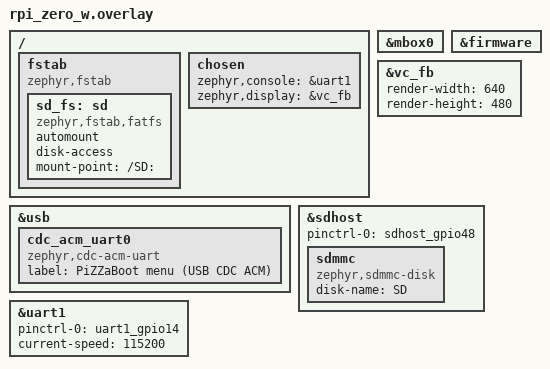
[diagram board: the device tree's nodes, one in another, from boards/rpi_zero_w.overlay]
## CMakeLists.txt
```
# SPDX-License-Identifier: Apache-2.0

cmake_minimum_required(VERSION 3.20.0)

find_package(Zephyr REQUIRED HINTS $ENV{ZEPHYR_BASE})
project(pizzaboot)

# USB CDC ACM menu mirror needs the usbd_context init helper from the
# Zephyr USB samples (same pattern as PizzaShell).
if(CONFIG_USB_DEVICE_STACK_NEXT)
  include(${ZEPHYR_BASE}/samples/subsys/usb/common/common.cmake)
endif()

target_sources(app PRIVATE
  src/main.c
  src/hdmi.c
  ../lib/bootsel/bootsel.c
)
target_include_directories(app PRIVATE ../lib ../lib/bootsel)
```

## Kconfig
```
# SPDX-License-Identifier: Apache-2.0

# Pull in the SAMPLE_USBD_* options used by sample_usbd_init.c (VID, PID,
# manufacturer/product strings) for the CDC menu mirror.
source "samples/subsys/usb/common/Kconfig.sample_usbd"

source "Kconfig.zephyr"
```

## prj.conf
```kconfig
# SPDX-License-Identifier: Apache-2.0
#
# PiZZaBoot -- Tier-1 boot menu. Deliberately dumb: no shell, no
# networking, no BT. Menu on mini-UART + USB CDC + HDMI; boots fast.

CONFIG_PRINTK=y
CONFIG_MAIN_STACK_SIZE=8192

CONFIG_SERIAL=y
CONFIG_UART_CONSOLE=y
CONFIG_UART_LINE_CTRL=y

CONFIG_GPIO=y

CONFIG_FILE_SYSTEM=y
CONFIG_FAT_FILESYSTEM_ELM=y
CONFIG_FS_FATFS_LFN=y
CONFIG_FS_FATFS_LFN_MODE_STACK=y

CONFIG_LOG=y
CONFIG_LOG_MODE_DEFERRED=y
CONFIG_LOG_BACKEND_UART=y
```

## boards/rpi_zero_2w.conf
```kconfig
# SPDX-License-Identifier: Apache-2.0
#
# PiZZaBoot on the Pi Zero 2 W: VC firmware mailbox (USB PHY power +
# HDMI fb), SDHost storage for the boot FAT, USB CDC menu mirror.

CONFIG_RASPBERRYPI_FIRMWARE=y

# HDMI menu via the VideoCore framebuffer
CONFIG_DISPLAY=y
CONFIG_BCM2835_FB=y

# Boot FAT on the microSD (SDHost); fstab automount in the overlay.
CONFIG_DISK_ACCESS=y
CONFIG_DISK_DRIVERS=y
CONFIG_SDMMC_SUBSYS=y
CONFIG_FS_FATFS_FSTAB_AUTOMOUNT=y
# Never reformat the boot card on a mount failure.
CONFIG_FILE_SYSTEM_MKFS=n
CONFIG_FS_FATFS_MOUNT_MKFS=n

# USB device stack -- CDC ACM menu mirror
CONFIG_USB_DEVICE_STACK_NEXT=y
CONFIG_UDC_DWC2=y
CONFIG_UDC_DWC2_DMA=n
CONFIG_USBD_CDC_ACM_CLASS=y
CONFIG_CDC_ACM_SERIAL_INITIALIZE_AT_BOOT=n
CONFIG_SAMPLE_USBD_PRODUCT="PiZZaBoot menu"
CONFIG_SAMPLE_USBD_MANUFACTURER="jetpax/PiZZa"
CONFIG_SAMPLE_USBD_PID=0xCAFE
# AArch64 USBD/UDC stacks: upstream defaults overflow.
CONFIG_USBD_THREAD_STACK_SIZE=4096
CONFIG_UDC_DWC2_STACK_SIZE=4096
CONFIG_UDC_DRIVER_LOG_LEVEL_WRN=y
CONFIG_USBD_CDC_ACM_LOG_LEVEL_WRN=y
CONFIG_USBD_LOG_LEVEL_WRN=y

# Bring-up nets; strip once M1 signs off.
CONFIG_STACK_SENTINEL=y
CONFIG_ASSERT=y
```

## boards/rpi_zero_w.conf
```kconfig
# SPDX-License-Identifier: Apache-2.0
#
# PiZZaBoot on the original Pi Zero W: VC firmware mailbox (USB PHY
# power + HDMI fb), SDHost storage for the boot FAT, USB CDC menu
# mirror. Mirrors the Zero 2 W config; the differences are noted.

CONFIG_RASPBERRYPI_FIRMWARE=y

# HDMI menu via the VideoCore framebuffer. The overlay pins a 640x480
# render size, so the buffer is 1.2 MB and fits the default 8 MiB
# KERNEL_VM_SIZE. Dropping render-width/height to take the monitor's
# native mode would need that raised -- a 1080p buffer is 8355840 bytes
# on its own and device_map() panics without the headroom.
CONFIG_DISPLAY=y
CONFIG_BCM2835_FB=y

# Boot FAT on the microSD (SDHost); fstab automount in the overlay.
CONFIG_DISK_ACCESS=y
CONFIG_DISK_DRIVERS=y
CONFIG_SDMMC_SUBSYS=y
CONFIG_FS_FATFS_FSTAB_AUTOMOUNT=y
# Never reformat the boot card on a mount failure.
CONFIG_FILE_SYSTEM_MKFS=n
CONFIG_FS_FATFS_MOUNT_MKFS=n

# USB device stack -- CDC ACM menu mirror
CONFIG_USB_DEVICE_STACK_NEXT=y
CONFIG_UDC_DWC2=y
CONFIG_UDC_DWC2_DMA=n
CONFIG_USBD_CDC_ACM_CLASS=y
CONFIG_CDC_ACM_SERIAL_INITIALIZE_AT_BOOT=n
CONFIG_SAMPLE_USBD_PRODUCT="PiZZaBoot menu"
CONFIG_SAMPLE_USBD_MANUFACTURER="jetpax/PiZZa"
CONFIG_SAMPLE_USBD_PID=0xCAFE
CONFIG_USBD_THREAD_STACK_SIZE=4096
CONFIG_UDC_DWC2_STACK_SIZE=4096
CONFIG_UDC_DRIVER_LOG_LEVEL_WRN=y
CONFIG_USBD_CDC_ACM_LOG_LEVEL_WRN=y
CONFIG_USBD_LOG_LEVEL_WRN=y

# Bring-up nets; strip once the Zero W menu signs off on hardware.
CONFIG_STACK_SENTINEL=y
CONFIG_ASSERT=y
```

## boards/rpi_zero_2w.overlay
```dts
/*
 * PiZZaBoot -- rpi_zero_2w overlay.
 *
 * Menu console on the mini-UART (GPIO14/15 @ 115200, per the canonical
 * config.txt enable_uart=1), mirrored on USB CDC ACM. HDMI list drawn
 * into a 640x480 virtual framebuffer that the VideoCore HVS upscales
 * to the monitor's native mode (render-width/render-height).
 */

&mbox0 {
	status = "okay";
};

&firmware {
	status = "okay";
};

&vc_fb {
	render-width = <640>;
	render-height = <480>;
	status = "okay";
};

&usb {
	status = "okay";

	cdc_acm_uart0: cdc_acm_uart0 {
		compatible = "zephyr,cdc-acm-uart";
		label = "PiZZaBoot menu (USB CDC ACM)";
	};
};

/ {
	fstab {
		compatible = "zephyr,fstab";

		sd_fs: sd {
			compatible = "zephyr,fstab,fatfs";
			automount;
			disk-access;
			mount-point = "/SD:";
		};
	};

	chosen {
		zephyr,console = &uart1;
		zephyr,display = &vc_fb;
	};
};

&uart1 {
	pinctrl-names = "default";
	pinctrl-0 = <&uart1_gpio14>;
	status = "okay";
	current-speed = <115200>;
};
```

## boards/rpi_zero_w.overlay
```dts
/*
 * PiZZaBoot -- rpi_zero_w overlay.
 *
 * Menu console on the mini-UART (GPIO14/15 @ 115200, per the canonical
 * config.txt enable_uart=1), mirrored on USB CDC ACM. HDMI list drawn
 * into a 640x480 virtual framebuffer that the VideoCore HVS upscales
 * to the monitor's native mode (render-width/render-height) -- the
 * same arrangement as the Zero 2 W, and it keeps the framebuffer at
 * 1.2 MB so the default 8 MiB kernel VM window is ample.
 *
 * Unlike the Zero 2 W, &sdhost is disabled in the SoC DTS and needs
 * its ALT0 mux (GPIO 48..53) named here.
 */

&mbox0 {
	status = "okay";
};

&firmware {
	status = "okay";
};

&vc_fb {
	render-width = <640>;
	render-height = <480>;
	status = "okay";
};

&usb {
	status = "okay";

	cdc_acm_uart0: cdc_acm_uart0 {
		compatible = "zephyr,cdc-acm-uart";
		label = "PiZZaBoot menu (USB CDC ACM)";
	};
};

/* Legacy SDHost controller -> external microSD slot, which carries the
 * boot FAT this menu reads menu.txt and chosen.txt from.
 */
&sdhost {
	pinctrl-names = "default";
	pinctrl-0 = <&sdhost_gpio48>;
	status = "okay";

	sdmmc {
		compatible = "zephyr,sdmmc-disk";
		disk-name = "SD";
	};
};

/ {
	fstab {
		compatible = "zephyr,fstab";

		sd_fs: sd {
			compatible = "zephyr,fstab,fatfs";
			automount;
			disk-access;
			mount-point = "/SD:";
		};
	};

	chosen {
		zephyr,console = &uart1;
		zephyr,display = &vc_fb;
	};
};

&uart1 {
	pinctrl-names = "default";
	pinctrl-0 = <&uart1_gpio14>;
	status = "okay";
	current-speed = <115200>;
};
```

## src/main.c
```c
/*
 * Copyright (c) 2026 jetpax <jetpax@users.noreply.github.com>
 * SPDX-License-Identifier: Apache-2.0
 *
 * PiZZaBoot -- the Tier-1 GRUB-style boot menu (WO-T1 M1).
 *
 * The GPU firmware is the actual boot selector: config.txt defaults to
 * this menu, `include chosen.txt` overrides it with the persisted
 * choice, and holding the GPIO17 button at power-on forces the menu
 * back. This app only has to render a list, take a pick, write
 * chosen.txt (atomically -- bootsel_set_kernel), and reset.
 *
 * UI surfaces, all driven from one poll loop:
 *   - mini-UART (115200 on GPIO14/15) -- ANSI menu, always on
 *   - USB CDC ACM -- same menu, mirrored while DTR is up
 *   - HDMI -- 8x8-font list (hdmi.c), optional
 *   - GPIO17 button -- short press = next entry, long press = boot
 *
 * Entries come from menu.txt on the boot FAT ("Name = file.bin" lines,
 * plus "timeout =" / "default ="); fallback is a *.bin scan. A countdown
 * to the default entry runs only when no valid chosen.txt exists (fresh
 * card); when the menu was summoned over a valid choice (the button
 * path), it waits for the user.
 */

#include <zephyr/kernel.h>
#include <zephyr/device.h>
#include <zephyr/devicetree.h>
#include <zephyr/drivers/uart.h>
#include <zephyr/drivers/gpio.h>
#include <zephyr/fs/fs.h>
#include <zephyr/sys/printk.h>
#include <stdarg.h>
#include <stdio.h>
#include <stdlib.h>
#include <string.h>

#include "bootsel.h"
#include "pizzaboot.h"

#if IS_ENABLED(CONFIG_USB_DEVICE_STACK_NEXT)
#include <zephyr/usb/usbd.h>
#include <sample_usbd.h>
#endif

#define MOUNT      "/SD:"
#define MENU_TXT   MOUNT "/menu.txt"
#define CHOSEN_TXT MOUNT "/chosen.txt"

#define DEFAULT_TIMEOUT_S 5
#define LONG_PRESS_MS     700
#define ESC_TIMEOUT_MS    60

/* --- boot entries ----------------------------------------------------------- */

static struct pb_entry entries[PB_MAX_ENTRIES];
static int entry_count;
static int menu_timeout_s = DEFAULT_TIMEOUT_S;
static char default_name[PB_NAME_LEN];

/* --- console mux ------------------------------------------------------------ */

enum key {
	K_NONE = 0,
	K_UP,
	K_DOWN,
	K_ENTER,
	K_OTHER,		/* any other key: cancels the countdown */
	K_DIGIT_BASE = 100,	/* K_DIGIT_BASE + i = entry i */
};

struct con {
	const struct device *dev;
	bool cdc;
	bool active;
	int esc;		/* 0 idle, 1 got ESC, 2 got ESC[ */
	int64_t esc_t;
};

static struct con cons[2];
static int con_count;

static void con_putc(char c)
{
	for (int i = 0; i < con_count; i++) {
		if (!cons[i].active) {
			continue;
		}
		if (c == '\n') {
			uart_poll_out(cons[i].dev, '\r');
		}
		uart_poll_out(cons[i].dev, c);
	}
}

static void con_puts(const char *s)
{
	for (; *s != '\0'; s++) {
		con_putc(*s);
	}
}

static void __printf_like(1, 2) con_printf(const char *fmt, ...)
{
	char buf[192];
	va_list ap;

	va_start(ap, fmt);
	vsnprintf(buf, sizeof(buf), fmt, ap);
	va_end(ap);
	con_puts(buf);
}

/* Throw away anything sitting in the RX FIFOs -- power-on line noise
 * lands there before the loop starts and must not cancel the countdown.
 */
static void con_drain(void)
{
	unsigned char junk;

	for (int i = 0; i < con_count; i++) {
		while (uart_poll_in(cons[i].dev, &junk) == 0) {
		}
	}
}

static enum key con_poll_key(struct con *c)
{
	unsigned char ch;

	while (uart_poll_in(c->dev, &ch) == 0) {
		if (c->esc == 1) {
			if (ch == '[') {
				c->esc = 2;
				continue;
			}
			c->esc = (ch == 0x1b) ? 1 : 0;
			continue;
		}
		if (c->esc == 2) {
			c->esc = 0;
			if (ch == 'A') {
				return K_UP;
			}
			if (ch == 'B') {
				return K_DOWN;
			}
			continue;
		}
		if (ch == 0x1b) {
			c->esc = 1;
			c->esc_t = k_uptime_get();
			continue;
		}
		if (ch == '\r' || ch == '\n') {
			return K_ENTER;
		}
		if (ch >= '1' && ch <= '9') {
			return (enum key)(K_DIGIT_BASE + (ch - '1'));
		}
		/* 0x00/0xFF are power-on line glitches, not keys. */
		if (ch == 0x00 || ch == 0xFF) {
			continue;
		}
		return K_OTHER;
	}

	/* Bare ESC (no sequence followed): treat as "a key". */
	if (c->esc == 1 && (k_uptime_get() - c->esc_t) > ESC_TIMEOUT_MS) {
		c->esc = 0;
		return K_OTHER;
	}
	return K_NONE;
}

/* --- USB CDC ---------------------------------------------------------------- */

#if IS_ENABLED(CONFIG_USB_DEVICE_STACK_NEXT)
static void usbd_cb(struct usbd_context *const ctx,
		    const struct usbd_msg *const msg)
{
	ARG_UNUSED(ctx);
	ARG_UNUSED(msg);
	/* DTR is polled from the main loop; nothing to do here. */
}

static void usb_start(void)
{
	struct usbd_context *usbd = sample_usbd_init_device(usbd_cb);

	if (usbd == NULL) {
		printk("[pizzaboot] usbd init failed\n");
		return;
	}
	if (!usbd_can_detect_vbus(usbd)) {
		int err = usbd_enable(usbd);

		if (err != 0) {
			printk("[pizzaboot] usbd_enable: %d\n", err);
		}
	}
}

static bool cdc_dtr(const struct device *dev)
{
	uint32_t dtr = 0U;

	(void)uart_line_ctrl_get(dev, UART_LINE_CTRL_DTR, &dtr);
	return dtr != 0U;
}
#else
static void usb_start(void)
{
}
#endif

/* --- GPIO17 button ----------------------------------------------------------- */

static const struct device *gpio0_dev;
static bool btn_ok;
static bool btn_down;
static bool btn_swallow;
static int64_t btn_t0;

static void button_init(void)
{
	gpio0_dev = DEVICE_DT_GET(DT_NODELABEL(gpio0));
	if (!device_is_ready(gpio0_dev)) {
		printk("[pizzaboot] gpio0 not ready, button off\n");
		return;
	}
	if (gpio_pin_configure(gpio0_dev, 17, GPIO_INPUT) == 0) {
		btn_ok = true;
		/* If the button is still down from summoning the menu
		 * (the firmware [gpio17=0] path), that press belongs to
		 * the firmware, not to us: swallow it until released.
		 */
		btn_swallow = gpio_pin_get_raw(gpio0_dev, 17) == 0;
	}
}

/* Short press = K_DOWN (cycle), long press = K_ENTER (boot). The pin
 * idles high (firmware gpio=17=ip,pu; button to GND), so pressed == 0.
 */
static enum key button_poll(void)
{
	if (!btn_ok) {
		return K_NONE;
	}

	bool pressed = gpio_pin_get_raw(gpio0_dev, 17) == 0;
	int64_t now = k_uptime_get();

	if (btn_swallow) {
		if (!pressed) {
			btn_swallow = false;
		}
		return K_NONE;
	}

	if (pressed && !btn_down) {
		btn_down = true;
		btn_t0 = now;
	} else if (!pressed && btn_down) {
		btn_down = false;
		if (now - btn_t0 >= LONG_PRESS_MS) {
			return K_ENTER;
		}
		if (now - btn_t0 >= 30) {	/* debounce */
			return K_DOWN;
		}
	}
	return K_NONE;
}

/* --- menu.txt ---------------------------------------------------------------- */

static char *trim(char *s)
{
	while (*s == ' ' || *s == '\t') {
		s++;
	}
	char *e = s + strlen(s);

	while (e > s && (e[-1] == ' ' || e[-1] == '\t' ||
			 e[-1] == '\r' || e[-1] == '\n')) {
		*--e = '\0';
	}
	return s;
}

static bool str_ieq(const char *a, const char *b)
{
	for (; *a != '\0' && *b != '\0'; a++, b++) {
		if ((*a | 0x20) != (*b | 0x20)) {
			return false;
		}
	}
	return *a == *b;
}

static int load_menu_txt(void)
{
	static char buf[2048];
	struct fs_file_t f;
	ssize_t n;

	fs_file_t_init(&f);
	if (fs_open(&f, MENU_TXT, FS_O_READ) != 0) {
		return 0;
	}
	n = fs_read(&f, buf, sizeof(buf) - 1);
	(void)fs_close(&f);
	if (n <= 0) {
		return 0;
	}
	buf[n] = '\0';

	int count = 0;
	char *save = NULL;

	for (char *line = strtok_r(buf, "\n", &save); line != NULL;
	     line = strtok_r(NULL, "\n", &save)) {
		char *s = trim(line);

		if (s[0] == '\0' || s[0] == '#') {
			continue;
		}
		char *eq = strchr(s, '=');

		if (eq == NULL) {
			continue;
		}
		*eq = '\0';
		char *key = trim(s);
		char *val = trim(eq + 1);

		if (str_ieq(key, "timeout")) {
			menu_timeout_s = atoi(val);
			continue;
		}
		if (str_ieq(key, "default")) {
			strncpy(default_name, val, sizeof(default_name) - 1);
			continue;
		}
		if (count < PB_MAX_ENTRIES && key[0] != '\0' &&
		    val[0] != '\0') {
			strncpy(entries[count].name, key, PB_NAME_LEN - 1);
			strncpy(entries[count].file, val, PB_FILE_LEN - 1);
			count++;
		}
	}
	return count;
}

/* Fallback when menu.txt is absent: every *.bin at the FAT root except
 * the GPU blob. Display name = filename minus .bin.
 */
static int scan_bins(void)
{
	struct fs_dir_t d;
	struct fs_dirent ent;
	int count = 0;

	fs_dir_t_init(&d);
	if (fs_opendir(&d, MOUNT) != 0) {
		return 0;
	}
	while (count < PB_MAX_ENTRIES && fs_readdir(&d, &ent) == 0 &&
	       ent.name[0] != '\0') {
		if (ent.type != FS_DIR_ENTRY_FILE || ent.name[0] == '.') {
			continue;
		}
		size_t len = strlen(ent.name);

		if (len < 5 || len >= PB_FILE_LEN ||
		    !str_ieq(ent.name + len - 4, ".bin")) {
			continue;
		}
		if (str_ieq(ent.name, "bootcode.bin")) {
			continue;
		}
		strncpy(entries[count].file, ent.name, PB_FILE_LEN - 1);
		memcpy(entries[count].name, ent.name,
		       MIN(len - 4, PB_NAME_LEN - 1));
		count++;
	}
	fs_closedir(&d);
	return count;
}

static void validate_entries(void)
{
	char path[PB_FILE_LEN + 8];
	struct fs_dirent st;

	for (int i = 0; i < entry_count; i++) {
		snprintf(path, sizeof(path), MOUNT "/%s", entries[i].file);
		entries[i].present = (fs_stat(path, &st) == 0 &&
				      st.type == FS_DIR_ENTRY_FILE);
	}
}

/* A valid chosen.txt means the firmware would have booted it -- we are
 * here because the button forced the menu, so no auto-boot countdown.
 */
static bool chosen_is_valid(void)
{
	char buf[64];
	char path[PB_FILE_LEN + 8];
	struct fs_dirent st;
	struct fs_file_t f;
	ssize_t n;

	fs_file_t_init(&f);
	if (fs_open(&f, CHOSEN_TXT, FS_O_READ) != 0) {
		return false;
	}
	n = fs_read(&f, buf, sizeof(buf) - 1);
	(void)fs_close(&f);
	if (n <= 0) {
		return false;
	}
	buf[n] = '\0';

	char *nl = strchr(buf, '\n');

	if (nl != NULL) {
		*nl = '\0';
	}
	if (strncmp(buf, "kernel=", 7) != 0) {
		return false;
	}
	snprintf(path, sizeof(path), MOUNT "/%s", trim(buf + 7));
	return fs_stat(path, &st) == 0 && st.type == FS_DIR_ENTRY_FILE;
}

/* --- rendering --------------------------------------------------------------- */

static void render(int sel, const char *status)
{
	con_puts("\x1b[2J\x1b[H");
	con_puts("PiZZaBoot -- select boot image\n\n");
	for (int i = 0; i < entry_count; i++) {
		con_printf("  %s%d. %-28s%s%s\n",
			   i == sel ? "\x1b[7m" : "",
			   i + 1, entries[i].name,
			   entries[i].present ? "" : " (missing)",
			   i == sel ? "\x1b[0m" : "");
	}
	if (entry_count == 0) {
		con_puts("  no boot entries found\n");
	}
	con_puts("\nup/down + enter, or a digit. button: short=next, long=boot\n");
	if (status != NULL && status[0] != '\0') {
		con_printf("%s\n", status);
	}
	hdmi_render(entries, entry_count, sel, status);
}

/* --- launch ------------------------------------------------------------------ */

static void launch(int idx, char *status, size_t status_sz)
{
	if (idx < 0 || idx >= entry_count) {
		return;
	}
	if (!entries[idx].present) {
		snprintf(status, status_sz, "%s: file missing",
			 entries[idx].name);
		return;
	}

	char msg[64];

	snprintf(msg, sizeof(msg), "booting %s ...", entries[idx].name);
	render(idx, msg);

	int rc = bootsel_set_kernel(entries[idx].file);

	if (rc != 0) {
		snprintf(status, status_sz, "chosen.txt write failed (%d)", rc);
		return;
	}
	k_msleep(50);
	bootsel_reboot();
}

/* --- main -------------------------------------------------------------------- */

int main(void)
{
	printk("[pizzaboot] WO-T1 M1\n");

	usb_start();
	button_init();
	(void)hdmi_init();

	cons[0].dev = DEVICE_DT_GET(DT_NODELABEL(uart1));
	cons[0].active = device_is_ready(cons[0].dev);
	con_count = 1;
#if DT_NODE_EXISTS(DT_NODELABEL(cdc_acm_uart0))
	cons[1].dev = DEVICE_DT_GET(DT_NODELABEL(cdc_acm_uart0));
	cons[1].cdc = true;
	cons[1].active = false;
	con_count = 2;
#endif

	/* The boot FAT is fstab-automounted; give a slow card a moment. */
	struct fs_dirent st;

	for (int i = 0; i < 20 && fs_stat(MENU_TXT, &st) == -ENOENT; i++) {
		if (fs_stat(MOUNT "/config.txt", &st) == 0) {
			break;
		}
		k_msleep(100);
	}

	entry_count = load_menu_txt();
	if (entry_count == 0) {
		entry_count = scan_bins();
	}
	validate_entries();

	bool countdown = !chosen_is_valid() && entry_count > 0;
	int shown_secs = -1;

	int sel = 0;

	if (default_name[0] != '\0') {
		for (int i = 0; i < entry_count; i++) {
			if (str_ieq(entries[i].name, default_name)) {
				sel = i;
				break;
			}
		}
	}

	char status[64] = "";

	if (countdown && menu_timeout_s <= 0) {
		launch(sel, status, sizeof(status));
		countdown = false;
	}

	render(sel, status);
	con_drain();

	int64_t deadline = k_uptime_get() + (int64_t)menu_timeout_s * 1000;

#if DT_NODE_EXISTS(DT_NODELABEL(cdc_acm_uart0))
	uint32_t tick = 0;
#endif

	for (;;) {
		enum key k = K_NONE;

		for (int i = 0; i < con_count && k == K_NONE; i++) {
			if (cons[i].active) {
				k = con_poll_key(&cons[i]);
			}
		}
		if (k == K_NONE) {
			k = button_poll();
		}

#if DT_NODE_EXISTS(DT_NODELABEL(cdc_acm_uart0))
		/* DTR poll ~10 Hz: activate/deactivate the CDC mirror. */
		if ((tick++ % 10) == 0) {
			bool up = cdc_dtr(cons[1].dev);

			if (up && !cons[1].active) {
				cons[1].active = true;
				render(sel, status);
			} else if (!up && cons[1].active) {
				cons[1].active = false;
			}
		}
#endif

		if (k != K_NONE && countdown) {
			countdown = false;
			status[0] = '\0';
			render(sel, status);
		}

		switch ((int)k) {
		case K_UP:
			if (entry_count > 0) {
				sel = (sel + entry_count - 1) % entry_count;
				render(sel, status);
			}
			break;
		case K_DOWN:
			if (entry_count > 0) {
				sel = (sel + 1) % entry_count;
				render(sel, status);
			}
			break;
		case K_ENTER:
			status[0] = '\0';
			launch(sel, status, sizeof(status));
			render(sel, status);
			break;
		default:
			if (k >= K_DIGIT_BASE &&
			    k < K_DIGIT_BASE + entry_count) {
				sel = k - K_DIGIT_BASE;
				status[0] = '\0';
				launch(sel, status, sizeof(status));
				render(sel, status);
			}
			break;
		}

		if (countdown) {
			int64_t left = deadline - k_uptime_get();

			if (left <= 0) {
				launch(sel, status, sizeof(status));
				countdown = false;
				render(sel, status);
			} else {
				int secs = (int)((left + 999) / 1000);

				if (secs != shown_secs) {
					shown_secs = secs;
					snprintf(status, sizeof(status),
						 "booting %s in %d s (any key stops)",
						 entries[sel].name, secs);
					render(sel, status);
				}
			}
		}

		k_msleep(10);
	}
	return 0;
}
```

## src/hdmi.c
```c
/*
 * Copyright (c) 2026 jetpax <jetpax@users.noreply.github.com>
 * SPDX-License-Identifier: Apache-2.0
 *
 * PiZZaBoot -- HDMI list renderer.
 *
 * Draws the boot menu into a static 640x480 ARGB buffer and pushes it
 * through the Zephyr display API (bcm2835_fb; the board overlay sets
 * render-width/render-height 640x480 so the VideoCore HVS upscales to
 * the monitor's native mode). Text is the same public-domain 8x8 font
 * the RetroPiZZa launcher uses; drawing code cribbed from
 * apps/retro/src/retro_menu.c.
 *
 * Headless (no monitor / display init failure) is a supported mode:
 * hdmi_init() failing just disables rendering, the serial menu is
 * unaffected.
 */

#include <zephyr/kernel.h>
#include <zephyr/device.h>
#include <zephyr/drivers/display.h>
#include <zephyr/sys/printk.h>
#include <string.h>

#include "pizzaboot.h"
#include "retro_font8x8.h"

#define FB_W 640
#define FB_H 480

/* Classic GRUB 0.5.x look: VGA blue field, white text, light bar.
 * Deliberately distinct from the RetroPiZZa launcher's dark theme so
 * the two full-screen lists are never mistaken for each other.
 */
#define COL_BG       0xFF0000A8u
#define COL_TEXT     0xFFFFFFFFu
#define COL_MISSING  0xFF9098C0u
#define COL_SEL_BG   0xFFE8E8E8u
#define COL_SEL_TEXT 0xFF0000A8u
#define COL_HELP     0xFFB8B8B8u

static const struct device *display_dev;
static bool hdmi_ok;
static uint32_t fb[FB_W * FB_H];

static void fill_rect(int x0, int y0, int w, int h, uint32_t argb)
{
	for (int y = y0; y < y0 + h && y < FB_H; y++) {
		if (y < 0) {
			continue;
		}
		uint32_t *row = fb + (size_t)y * FB_W;

		for (int x = x0; x < x0 + w && x < FB_W; x++) {
			if (x >= 0) {
				row[x] = argb;
			}
		}
	}
}

static void draw_char(int x, int y, char c, int scale, uint32_t argb)
{
	if ((uint8_t)c < RETRO_FONT_FIRST || (uint8_t)c > RETRO_FONT_LAST) {
		c = '?';
	}
	const uint8_t *g = retro_font8x8[(uint8_t)c - RETRO_FONT_FIRST];

	for (int row = 0; row < 8; row++) {
		for (int col = 0; col < 8; col++) {
			if (g[row] & (1u << col)) {
				fill_rect(x + col * scale, y + row * scale,
					  scale, scale, argb);
			}
		}
	}
}

static void draw_text(int x, int y, const char *s, int scale, uint32_t argb)
{
	for (; *s != '\0'; s++) {
		draw_char(x, y, *s, scale, argb);
		x += 8 * scale + scale;
	}
}

int hdmi_init(void)
{
	if (!DT_HAS_CHOSEN(zephyr_display)) {
		return -ENODEV;
	}
	display_dev = DEVICE_DT_GET(DT_CHOSEN(zephyr_display));
	if (!device_is_ready(display_dev)) {
		printk("[pizzaboot] display not ready, HDMI menu off\n");
		return -ENODEV;
	}

	struct display_capabilities caps;

	display_get_capabilities(display_dev, &caps);
	if (caps.x_resolution != FB_W || caps.y_resolution != FB_H) {
		printk("[pizzaboot] display %ux%u != %ux%u, HDMI menu off\n",
		       caps.x_resolution, caps.y_resolution, FB_W, FB_H);
		return -EINVAL;
	}

	hdmi_ok = true;
	return 0;
}

void hdmi_render(const struct bootsel_entry *ents, int n, int sel,
		 const char *status)
{
	if (!hdmi_ok) {
		return;
	}

	const int item_scale = 2;
	const int row_h = 8 * item_scale + 8;
	const int box_x = 12;
	const int box_y = 44;
	const int box_w = FB_W - 2 * box_x;
	const int box_rows = 12;
	const int box_h = box_rows * row_h + 12;
	const int list_x = box_x + 16;
	const int list_top = box_y + 10;

	for (int i = 0; i < FB_W * FB_H; i++) {
		fb[i] = COL_BG;
	}

	draw_text(box_x, 14, "PiZZaBoot  version " PIZZA_VERSION, 2,
		  COL_TEXT);

	fill_rect(box_x, box_y, box_w, 2, COL_TEXT);
	fill_rect(box_x, box_y + box_h - 2, box_w, 2, COL_TEXT);
	fill_rect(box_x, box_y, 2, box_h, COL_TEXT);
	fill_rect(box_x + box_w - 2, box_y, 2, box_h, COL_TEXT);

	if (n == 0) {
		draw_text(list_x, list_top, "no boot entries", item_scale,
			  COL_TEXT);
	}

	for (int i = 0; i < n && i < PB_MAX_ENTRIES; i++) {
		int y = list_top + i * row_h;
		uint32_t col = ents[i].present ? COL_TEXT : COL_MISSING;

		if (i == sel) {
			fill_rect(box_x + 2, y - 3, box_w - 4, row_h,
				  COL_SEL_BG);
			col = ents[i].present ? COL_SEL_TEXT : COL_MISSING;
		}
		draw_text(list_x, y, ents[i].name, item_scale, col);
		if (!ents[i].present) {
			draw_text(box_x + box_w - 100, y + 4, "(missing)", 1,
				  col == COL_SEL_TEXT ? COL_SEL_TEXT :
				  COL_MISSING);
		}
	}

	int hy = box_y + box_h + 16;

	draw_text(box_x + 8, hy,
		  "Use the up and down arrows (or short button presses) to",
		  1, COL_HELP);
	draw_text(box_x + 8, hy + 14,
		  "select which entry is highlighted.", 1, COL_HELP);
	draw_text(box_x + 8, hy + 34,
		  "Press enter or a digit, or hold the button, to boot the",
		  1, COL_HELP);
	draw_text(box_x + 8, hy + 48,
		  "selected image.", 1, COL_HELP);

	if (status != NULL && status[0] != '\0') {
		draw_text(box_x + 8, FB_H - 30, status, 1, COL_TEXT);
	}

	struct display_buffer_descriptor desc = {
		.buf_size = (size_t)FB_W * FB_H * 4,
		.width = FB_W,
		.height = FB_H,
		.pitch = FB_W,
		.frame_incomplete = false,
	};

	(void)display_write(display_dev, 0, 0, &desc, fb);
}
```

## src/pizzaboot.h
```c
/*
 * Copyright (c) 2026 jetpax <jetpax@users.noreply.github.com>
 * SPDX-License-Identifier: Apache-2.0
 */

#ifndef PIZZABOOT_H_
#define PIZZABOOT_H_

#include "bootsel.h"
#include "pizza_version.h"

#define PB_MAX_ENTRIES BOOTSEL_MAX_ENTRIES
#define PB_NAME_LEN    BOOTSEL_NAME_LEN
#define PB_FILE_LEN    BOOTSEL_FILE_LEN

/* HDMI list renderer (hdmi.c). status may be NULL. */
int hdmi_init(void);
void hdmi_render(const struct bootsel_entry *ents, int n, int sel,
		 const char *status);

#endif /* PIZZABOOT_H_ */
```

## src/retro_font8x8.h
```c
/*
 * SPDX-License-Identifier: Unlicense
 *
 * 8x8 monochrome bitmap font, public-domain "font8x8_basic" (Daniel
 * Hepper, github.com/dhepper/font8x8). Printable ASCII 0x20..0x7F,
 * indexed by (ch - 0x20). Each glyph is 8 rows; in each row byte, bit 0
 * (LSB) is the leftmost pixel.
 */

#ifndef PIZZA_RETRO_FONT8X8_H
#define PIZZA_RETRO_FONT8X8_H

#include <stdint.h>

#define RETRO_FONT_FIRST 0x20
#define RETRO_FONT_LAST  0x7F

static const uint8_t retro_font8x8[RETRO_FONT_LAST - RETRO_FONT_FIRST + 1][8] = {
	{ 0x00, 0x00, 0x00, 0x00, 0x00, 0x00, 0x00, 0x00 }, /* 0x20 ' ' */
	{ 0x18, 0x3C, 0x3C, 0x18, 0x18, 0x00, 0x18, 0x00 }, /* ! */
	{ 0x36, 0x36, 0x00, 0x00, 0x00, 0x00, 0x00, 0x00 }, /* " */
	{ 0x36, 0x36, 0x7F, 0x36, 0x7F, 0x36, 0x36, 0x00 }, /* # */
	{ 0x0C, 0x3E, 0x03, 0x1E, 0x30, 0x1F, 0x0C, 0x00 }, /* $ */
	{ 0x00, 0x63, 0x33, 0x18, 0x0C, 0x66, 0x63, 0x00 }, /* % */
	{ 0x1C, 0x36, 0x1C, 0x6E, 0x3B, 0x33, 0x6E, 0x00 }, /* & */
	{ 0x06, 0x06, 0x03, 0x00, 0x00, 0x00, 0x00, 0x00 }, /* ' */
	{ 0x18, 0x0C, 0x06, 0x06, 0x06, 0x0C, 0x18, 0x00 }, /* ( */
	{ 0x06, 0x0C, 0x18, 0x18, 0x18, 0x0C, 0x06, 0x00 }, /* ) */
	{ 0x00, 0x66, 0x3C, 0xFF, 0x3C, 0x66, 0x00, 0x00 }, /* * */
	{ 0x00, 0x0C, 0x0C, 0x3F, 0x0C, 0x0C, 0x00, 0x00 }, /* + */
	{ 0x00, 0x00, 0x00, 0x00, 0x00, 0x0C, 0x0C, 0x06 }, /* , */
	{ 0x00, 0x00, 0x00, 0x3F, 0x00, 0x00, 0x00, 0x00 }, /* - */
	{ 0x00, 0x00, 0x00, 0x00, 0x00, 0x0C, 0x0C, 0x00 }, /* . */
	{ 0x60, 0x30, 0x18, 0x0C, 0x06, 0x03, 0x01, 0x00 }, /* / */
	{ 0x3E, 0x63, 0x73, 0x7B, 0x6F, 0x67, 0x3E, 0x00 }, /* 0 */
	{ 0x0C, 0x0E, 0x0C, 0x0C, 0x0C, 0x0C, 0x3F, 0x00 }, /* 1 */
	{ 0x1E, 0x33, 0x30, 0x1C, 0x06, 0x33, 0x3F, 0x00 }, /* 2 */
	{ 0x1E, 0x33, 0x30, 0x1C, 0x30, 0x33, 0x1E, 0x00 }, /* 3 */
	{ 0x38, 0x3C, 0x36, 0x33, 0x7F, 0x30, 0x78, 0x00 }, /* 4 */
	{ 0x3F, 0x03, 0x1F, 0x30, 0x30, 0x33, 0x1E, 0x00 }, /* 5 */
	{ 0x1C, 0x06, 0x03, 0x1F, 0x33, 0x33, 0x1E, 0x00 }, /* 6 */
	{ 0x3F, 0x33, 0x30, 0x18, 0x0C, 0x0C, 0x0C, 0x00 }, /* 7 */
	{ 0x1E, 0x33, 0x33, 0x1E, 0x33, 0x33, 0x1E, 0x00 }, /* 8 */
	{ 0x1E, 0x33, 0x33, 0x3E, 0x30, 0x18, 0x0E, 0x00 }, /* 9 */
	{ 0x00, 0x0C, 0x0C, 0x00, 0x00, 0x0C, 0x0C, 0x00 }, /* : */
	{ 0x00, 0x0C, 0x0C, 0x00, 0x00, 0x0C, 0x0C, 0x06 }, /* ; */
	{ 0x18, 0x0C, 0x06, 0x03, 0x06, 0x0C, 0x18, 0x00 }, /* < */
	{ 0x00, 0x00, 0x3F, 0x00, 0x00, 0x3F, 0x00, 0x00 }, /* = */
	{ 0x06, 0x0C, 0x18, 0x30, 0x18, 0x0C, 0x06, 0x00 }, /* > */
	{ 0x1E, 0x33, 0x30, 0x18, 0x0C, 0x00, 0x0C, 0x00 }, /* ? */
	{ 0x3E, 0x63, 0x7B, 0x7B, 0x7B, 0x03, 0x1E, 0x00 }, /* @ */
	{ 0x0C, 0x1E, 0x33, 0x33, 0x3F, 0x33, 0x33, 0x00 }, /* A */
	{ 0x3F, 0x66, 0x66, 0x3E, 0x66, 0x66, 0x3F, 0x00 }, /* B */
	{ 0x3C, 0x66, 0x03, 0x03, 0x03, 0x66, 0x3C, 0x00 }, /* C */
	{ 0x1F, 0x36, 0x66, 0x66, 0x66, 0x36, 0x1F, 0x00 }, /* D */
	{ 0x7F, 0x46, 0x16, 0x1E, 0x16, 0x46, 0x7F, 0x00 }, /* E */
	{ 0x7F, 0x46, 0x16, 0x1E, 0x16, 0x06, 0x0F, 0x00 }, /* F */
	{ 0x3C, 0x66, 0x03, 0x03, 0x73, 0x66, 0x7C, 0x00 }, /* G */
	{ 0x33, 0x33, 0x33, 0x3F, 0x33, 0x33, 0x33, 0x00 }, /* H */
	{ 0x1E, 0x0C, 0x0C, 0x0C, 0x0C, 0x0C, 0x1E, 0x00 }, /* I */
	{ 0x78, 0x30, 0x30, 0x30, 0x33, 0x33, 0x1E, 0x00 }, /* J */
	{ 0x67, 0x66, 0x36, 0x1E, 0x36, 0x66, 0x67, 0x00 }, /* K */
	{ 0x0F, 0x06, 0x06, 0x06, 0x46, 0x66, 0x7F, 0x00 }, /* L */
	{ 0x63, 0x77, 0x7F, 0x7F, 0x6B, 0x63, 0x63, 0x00 }, /* M */
	{ 0x63, 0x67, 0x6F, 0x7B, 0x73, 0x63, 0x63, 0x00 }, /* N */
	{ 0x1C, 0x36, 0x63, 0x63, 0x63, 0x36, 0x1C, 0x00 }, /* O */
	{ 0x3F, 0x66, 0x66, 0x3E, 0x06, 0x06, 0x0F, 0x00 }, /* P */
	{ 0x1E, 0x33, 0x33, 0x33, 0x3B, 0x1E, 0x38, 0x00 }, /* Q */
	{ 0x3F, 0x66, 0x66, 0x3E, 0x36, 0x66, 0x67, 0x00 }, /* R */
	{ 0x1E, 0x33, 0x07, 0x0E, 0x38, 0x33, 0x1E, 0x00 }, /* S */
	{ 0x3F, 0x2D, 0x0C, 0x0C, 0x0C, 0x0C, 0x1E, 0x00 }, /* T */
	{ 0x33, 0x33, 0x33, 0x33, 0x33, 0x33, 0x3F, 0x00 }, /* U */
	{ 0x33, 0x33, 0x33, 0x33, 0x33, 0x1E, 0x0C, 0x00 }, /* V */
	{ 0x63, 0x63, 0x63, 0x6B, 0x7F, 0x77, 0x63, 0x00 }, /* W */
	{ 0x63, 0x63, 0x36, 0x1C, 0x1C, 0x36, 0x63, 0x00 }, /* X */
	{ 0x33, 0x33, 0x33, 0x1E, 0x0C, 0x0C, 0x1E, 0x00 }, /* Y */
	{ 0x7F, 0x63, 0x31, 0x18, 0x4C, 0x66, 0x7F, 0x00 }, /* Z */
	{ 0x1E, 0x06, 0x06, 0x06, 0x06, 0x06, 0x1E, 0x00 }, /* [ */
	{ 0x03, 0x06, 0x0C, 0x18, 0x30, 0x60, 0x40, 0x00 }, /* \ */
	{ 0x1E, 0x18, 0x18, 0x18, 0x18, 0x18, 0x1E, 0x00 }, /* ] */
	{ 0x08, 0x1C, 0x36, 0x63, 0x00, 0x00, 0x00, 0x00 }, /* ^ */
	{ 0x00, 0x00, 0x00, 0x00, 0x00, 0x00, 0x00, 0xFF }, /* _ */
	{ 0x0C, 0x0C, 0x18, 0x00, 0x00, 0x00, 0x00, 0x00 }, /* ` */
	{ 0x00, 0x00, 0x1E, 0x30, 0x3E, 0x33, 0x6E, 0x00 }, /* a */
	{ 0x07, 0x06, 0x06, 0x3E, 0x66, 0x66, 0x3B, 0x00 }, /* b */
	{ 0x00, 0x00, 0x1E, 0x33, 0x03, 0x33, 0x1E, 0x00 }, /* c */
	{ 0x38, 0x30, 0x30, 0x3E, 0x33, 0x33, 0x6E, 0x00 }, /* d */
	{ 0x00, 0x00, 0x1E, 0x33, 0x3F, 0x03, 0x1E, 0x00 }, /* e */
	{ 0x1C, 0x36, 0x06, 0x0F, 0x06, 0x06, 0x0F, 0x00 }, /* f */
	{ 0x00, 0x00, 0x6E, 0x33, 0x33, 0x3E, 0x30, 0x1F }, /* g */
	{ 0x07, 0x06, 0x36, 0x6E, 0x66, 0x66, 0x67, 0x00 }, /* h */
	{ 0x0C, 0x00, 0x0E, 0x0C, 0x0C, 0x0C, 0x1E, 0x00 }, /* i */
	{ 0x30, 0x00, 0x30, 0x30, 0x30, 0x33, 0x33, 0x1E }, /* j */
	{ 0x07, 0x06, 0x66, 0x36, 0x1E, 0x36, 0x67, 0x00 }, /* k */
	{ 0x0E, 0x0C, 0x0C, 0x0C, 0x0C, 0x0C, 0x1E, 0x00 }, /* l */
	{ 0x00, 0x00, 0x33, 0x7F, 0x7F, 0x6B, 0x63, 0x00 }, /* m */
	{ 0x00, 0x00, 0x1F, 0x33, 0x33, 0x33, 0x33, 0x00 }, /* n */
	{ 0x00, 0x00, 0x1E, 0x33, 0x33, 0x33, 0x1E, 0x00 }, /* o */
	{ 0x00, 0x00, 0x3B, 0x66, 0x66, 0x3E, 0x06, 0x0F }, /* p */
	{ 0x00, 0x00, 0x6E, 0x33, 0x33, 0x3E, 0x30, 0x78 }, /* q */
	{ 0x00, 0x00, 0x3B, 0x6E, 0x66, 0x06, 0x0F, 0x00 }, /* r */
	{ 0x00, 0x00, 0x3E, 0x03, 0x1E, 0x30, 0x1F, 0x00 }, /* s */
	{ 0x08, 0x0C, 0x3E, 0x0C, 0x0C, 0x2C, 0x18, 0x00 }, /* t */
	{ 0x00, 0x00, 0x33, 0x33, 0x33, 0x33, 0x6E, 0x00 }, /* u */
	{ 0x00, 0x00, 0x33, 0x33, 0x33, 0x1E, 0x0C, 0x00 }, /* v */
	{ 0x00, 0x00, 0x63, 0x6B, 0x7F, 0x7F, 0x36, 0x00 }, /* w */
	{ 0x00, 0x00, 0x63, 0x36, 0x1C, 0x36, 0x63, 0x00 }, /* x */
	{ 0x00, 0x00, 0x33, 0x33, 0x33, 0x3E, 0x30, 0x1F }, /* y */
	{ 0x00, 0x00, 0x3F, 0x19, 0x0C, 0x26, 0x3F, 0x00 }, /* z */
	{ 0x38, 0x0C, 0x0C, 0x07, 0x0C, 0x0C, 0x38, 0x00 }, /* { */
	{ 0x18, 0x18, 0x18, 0x00, 0x18, 0x18, 0x18, 0x00 }, /* | */
	{ 0x07, 0x0C, 0x0C, 0x38, 0x0C, 0x0C, 0x07, 0x00 }, /* } */
	{ 0x6E, 0x3B, 0x00, 0x00, 0x00, 0x00, 0x00, 0x00 }, /* ~ */
	{ 0x00, 0x00, 0x00, 0x00, 0x00, 0x00, 0x00, 0x00 }, /* 0x7F */
};

#endif /* PIZZA_RETRO_FONT8X8_H */
```
